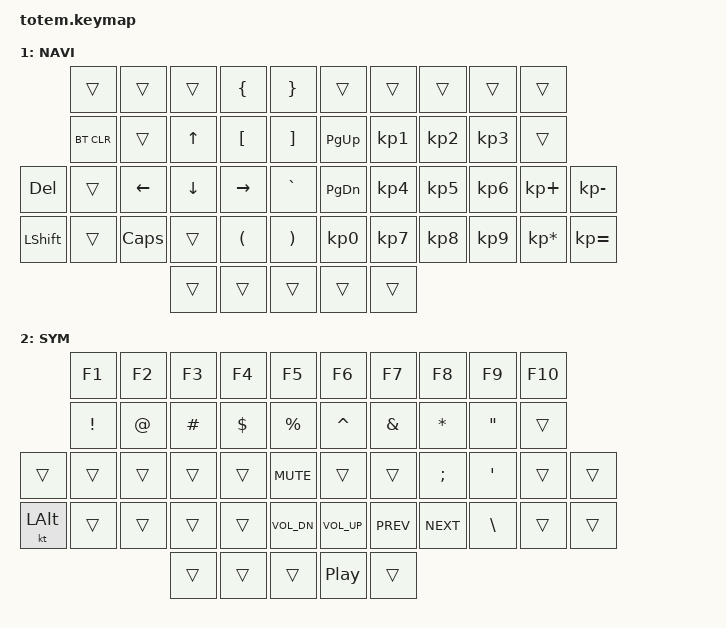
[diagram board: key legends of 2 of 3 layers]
//
//                                                        ▀▀▀▀▀     ▀▀▀▀▀          ▀▀█▀▀
//                                                        ▄▀▀▀▄  ▄  ▄▀▀▀▄  ▄  ▄▀▀▀▄  █  ▄▀▀▀▄
//                                                        █   █  █  █   █  █  █   █  █  █   █
//                                                         ▀▀▀   █   ▀▀▀   █   ▀▀▀   ▀   ▀▀▀
//                                                               █      ▄▄▄█▄▄▄    █   █
//                                                               ▀      █  █  █     █▄█
//                                                             ▀▀▀▀▀    █  █  █      ▀
//                                                                      ▀  ▀  ▀
//
// ▄▄▄▄▄▄▄▄▄▄▄▄▄▄▄▄▄▄▄▄▄▄▄▄▄▄▄▄▄▄▄▄▄▄▄▄▄▄▄▄▄▄▄▄▄▄▄▄▄▄▄▄▄▄▄▄▄▄▄▄▄▄▄▄▄▄▄▄▄▄▄▄▄▄▄▄▄▄▄▄▄▄▄▄▄▄▄▄▄▄▄▄▄▄▄▄▄▄▄▄▄▄▄▄▄▄▄▄▄▄▄▄▄▄▄▄▄▄▄▄▄▄▄▄▄▄▄▄▄▄▄▄▄▄▄▄▄▄▄▄▄▄▄▄▄▄▄▄▄

#include <behaviors.dtsi>
#include <dt-bindings/zmk/bt.h>
#include <dt-bindings/zmk/keys.h>

#define BASE 0
#define NAV  1
#define SYM  2
#define ADJ  3
#define TVP1 4
#define TVP2 5

&mt {
    quick-tap-ms = <100>;
    global-quick-tap;
    flavor = "tap-preferred";
    tapping-term-ms = <170>;
};

&lt {
    tapping-term-ms = <200>;
    flavor = "hold-preferred";
    quick-tap-ms = <125>;
};

/ {
    combos {
        compatible = "zmk,combos";

        combo_esc {
            timeout-ms = <50>;
            key-positions = <0 1>;
            bindings = <&kp ESC>;
        };

        combo_tvp {
            timeout-ms = <100>;
            key-positions = <11 12 13>;
            bindings = <&tog 0>;
        };
    };

    macros {
        gif: gif {
            label = "giphy";
            compatible = "zmk,behavior-macro";
            #binding-cells = <0>;
            bindings =
                <&macro_press>,
                <&kp LSHFT>,
                <&macro_tap>,
                <&kp N2>,
                <&macro_release>,
                <&kp LSHFT>,
                <&macro_tap>,
                <&kp G &kp I &kp F>;
        };
    };

    keymap {
        compatible = "zmk,keymap";

        // ▄▄▄▄▄▄▄▄▄▄▄▄▄▄▄▄▄▄▄▄▄▄▄▄▄▄▄▄▄▄▄▄▄▄▄▄▄▄▄▄▄▄▄▄▄▄▄▄▄▄▄▄▄▄▄▄▄▄▄▄▄▄▄▄▄▄▄▄▄▄▄▄▄▄▄▄▄▄▄▄▄▄▄▄▄▄▄▄▄▄▄▄▄▄▄▄▄▄▄▄▄▄▄▄▄▄▄▄▄▄▄▄▄▄▄▄▄▄▄▄▄▄▄▄▄▄▄▄▄▄▄▄▄▄▄▄▄▄▄▄▄▄▄▄▄▄▄▄▄

        base_layer {
            // ┏━━━━━━━━━━━━━━━━━━━━━━━━━━━━━━━━━━━━━━━┓

            label = "BASE";

            // ┗━━━━━━━━━━━━━━━━━━━━━━━━━━━━━━━━━━━━━━━┛
            // ┏━━━━━━━━━━━┳━━━━━━━━━━━┳━━━━━━━━━━━┳━━━━━━━━━━━┳━━━━━━━━━━━┓               ┏━━━━━━━━━━━┳━━━━━━━━━━━┳━━━━━━━━━━━┳━━━━━━━━━━━┳━━━━━━━━━━━┓
            // ┃     1     ┃     2     ┃     3     ┃     4     ┃     5     ┃               ┃     6     ┃     7     ┃     8     ┃     9     ┃     0     ┃
            // ┣━━━━━━━━━━━╋━━━━━━━━━━━╋━━━━━━━━━━━╋━━━━━━━━━━━╋━━━━━━━━━━━┫               ┣━━━━━━━━━━━╋━━━━━━━━━━━╋━━━━━━━━━━━╋━━━━━━━━━━━╋━━━━━━━━━━━┫
            //             ┃     Q     ┃     W     ┃     F     ┃     P     ┃     G     ┃   ┃     J     ┃     L     ┃     U     ┃     Y     ┃     ;     ┃
            //             ┣━━━━━━━━━━━╋━━━━━━━━━━━╋━━━━━━━━━━━╋━━━━━━━━━━━╋━━━━━━━━━━━┫   ┣━━━━━━━━━━━╋━━━━━━━━━━━╋━━━━━━━━━━━╋━━━━━━━━━━━╋━━━━━━━━━━━┫
            //             ┃     A     ┃     R     ┃     S     ┃     T     ┃     D     ┃   ┃     H     ┃     N     ┃     E     ┃     I     ┃     O     ┃
            // ┏━━━━━━━━━━━╋━━━━━━━━━━━╋━━━━━━━━━━━╋━━━━━━━━━━━╋━━━━━━━━━━━╋━━━━━━━━━━━┫   ┣━━━━━━━━━━━╋━━━━━━━━━━━╋━━━━━━━━━━━╋━━━━━━━━━━━╋━━━━━━━━━━━╋━━━━━━━━━━━┓
            // ┃     Q     ┃     Z     ┃     X     ┃     C     ┃     V     ┃     B     ┃   ┃     K     ┃     M     ┃     ,     ┃     .     ┃     /     ┃     \     ┃
            // ┗━━━━━━━━━━━┻━━━━━━━━━━━┻━━━━━━━━━━━╋━━━━━━━━━━━╋━━━━━━━━━━━╋━━━━━━━━━━━┫   ┣━━━━━━━━━━━╋━━━━━━━━━━━╋━━━━━━━━━━━╋━━━━━━━━━━━┻━━━━━━━━━━━┻━━━━━━━━━━━┛
            //                                     ┃    DEL    ┃    TAB    ┃    SPC    ┃   ┃   ENTER   ┃           ┃   BSPC    ┃
            //                                     ┗━━━━━━━━━━━┻━━━━━━━━━━━┻━━━━━━━━━━━┛   ┗━━━━━━━━━━━┻━━━━━━━━━━━┻━━━━━━━━━━━┛

            bindings = <
                &kp NUMBER_1  &kp NUMBER_2  &kp NUMBER_3      &kp NUMBER_4  &kp N5       &kp NUMBER_6  &kp N7           &kp N8       &kp N9      &kp N0
                &kp Q         &kp W         &kp E             &kp R         &kp T        &kp Y         &kp U            &kp I        &kp O       &kp P
&kp ESCAPE      &mt LGUI A    &mt LALT S    &mt LCTRL D       &mt LSHFT F   &kp G        &kp H         &mt RSHFT J      &mt RCTRL K  &mt RALT L  &mt RGUI DOUBLE_QUOTES  &kp MINUS
&kp LEFT_SHIFT  &kp Z         &kp X         &kp C             &kp V         &kp B        &kp N         &kp M            &kp COMMA    &kp DOT     &kp FSLH                &kp EQUAL
                                            &mt LCTRL ESCAPE  &lt 1 TAB     &kp SPACE    &kp SPACE     &lt 2 BACKSPACE  &kp ENTER
            >;
        };

        // ▄▄▄▄▄▄▄▄▄▄▄▄▄▄▄▄▄▄▄▄▄▄▄▄▄▄▄▄▄▄▄▄▄▄▄▄▄▄▄▄▄▄▄▄▄▄▄▄▄▄▄▄▄▄▄▄▄▄▄▄▄▄▄▄▄▄▄▄▄▄▄▄▄▄▄▄▄▄▄▄▄▄▄▄▄▄▄▄▄▄▄▄▄▄▄▄▄▄▄▄▄▄▄▄▄▄▄▄▄▄▄▄▄▄▄▄▄▄▄▄▄▄▄▄▄▄▄▄▄▄▄▄▄▄▄▄▄▄▄▄▄▄▄▄▄▄▄▄▄

        nav_layer {
            // ┏━━━━━━━━━━━━━━━━━━━━━━━━━━━━━━━━━━━━━━━┓

            label = "NAVI";

            // ┗━━━━━━━━━━━━━━━━━━━━━━━━━━━━━━━━━━━━━━━┛
            // ┏━━━━━━━━━━━┳━━━━━━━━━━━┳━━━━━━━━━━━┳━━━━━━━━━━━┳━━━━━━━━━━━┓   ┏━━━━━━━━━━━┳━━━━━━━━━━━┳━━━━━━━━━━━┳━━━━━━━━━━━┳━━━━━━━━━━━┓
            // ┃           ┃           ┃           ┃           ┃           ┃   ┃           ┃           ┃           ┃           ┃           ┃
            // ┣━━━━━━━━━━━╋━━━━━━━━━━━╋━━━━━━━━━━━╋━━━━━━━━━━━╋━━━━━━━━━━━┫   ┣━━━━━━━━━━━╋━━━━━━━━━━━╋━━━━━━━━━━━╋━━━━━━━━━━━╋━━━━━━━━━━━┫
            //             ┃           ┃           ┃     UP    ┃           ┃     {     ┃   ┃     }     ┃     7     ┃     8     ┃     9     ┃     +     ┃
            //             ┣━━━━━━━━━━━╋━━━━━━━━━━━╋━━━━━━━━━━━╋━━━━━━━━━━━╋━━━━━━━━━━━┫   ┣━━━━━━━━━━━╋━━━━━━━━━━━╋━━━━━━━━━━━╋━━━━━━━━━━━╋━━━━━━━━━━━┫
            //             ┃   SHIFT   ┃   LEFT    ┃    DOWN   ┃   RIGHT   ┃     [     ┃   ┃     ]     ┃     4     ┃     5     ┃     6     ┃     -     ┃
            // ┏━━━━━━━━━━━╋━━━━━━━━━━━╋━━━━━━━━━━━╋━━━━━━━━━━━╋━━━━━━━━━━━╋━━━━━━━━━━━┫   ┣━━━━━━━━━━━╋━━━━━━━━━━━╋━━━━━━━━━━━╋━━━━━━━━━━━╋━━━━━━━━━━━╋━━━━━━━━━━━┓
            // ┃           ┃           ┃   P UP    ┃  C LOCK   ┃  P DOWN   ┃     (     ┃   ┃     )     ┃     1     ┃     2     ┃     3     ┃     *     ┃           ┃
            // ┗━━━━━━━━━━━┻━━━━━━━━━━━┻━━━━━━━━━━━╋━━━━━━━━━━━╋━━━━━━━━━━━╋━━━━━━━━━━━┫   ┣━━━━━━━━━━━╋━━━━━━━━━━━╋━━━━━━━━━━━╋━━━━━━━━━━━┻━━━━━━━━━━━┻━━━━━━━━━━━┛
            //                                     ┃           ┃    TAB    ┃    SPC    ┃   ┃    DEL    ┃     0     ┃           ┃
            //                                     ┗━━━━━━━━━━━┻━━━━━━━━━━━┻━━━━━━━━━━━┛   ┗━━━━━━━━━━━┻━━━━━━━━━━━┻━━━━━━━━━━━┛

            bindings = <
                &trans      &trans    &trans        &kp LEFT_BRACE    &kp RIGHT_BRACE      &trans         &trans           &trans           &trans           &trans
                &bt BT_CLR  &trans    &kp UP_ARROW  &kp LEFT_BRACKET  &kp RIGHT_BRACKET    &kp PAGE_UP    &kp KP_NUMBER_1  &kp KP_N2        &kp KP_NUMBER_3  &trans
&kp DEL         &trans      &kp LEFT  &kp DOWN      &kp RIGHT         &kp GRAVE            &kp PAGE_DOWN  &kp KP_NUMBER_4  &kp KP_NUMBER_5  &kp KP_N6        &kp KP_PLUS      &kp KP_MINUS
&kp LEFT_SHIFT  &trans      &kp CAPS  &trans        &kp LPAR          &kp RPAR             &kp KP_N0      &kp KP_NUMBER_7  &kp KP_NUMBER_8  &kp KP_NUMBER_9  &kp KP_MULTIPLY  &kp KP_EQUAL
                                      &trans        &trans            &trans               &trans         &trans
            >;
        };

        // ▄▄▄▄▄▄▄▄▄▄▄▄▄▄▄▄▄▄▄▄▄▄▄▄▄▄▄▄▄▄▄▄▄▄▄▄▄▄▄▄▄▄▄▄▄▄▄▄▄▄▄▄▄▄▄▄▄▄▄▄▄▄▄▄▄▄▄▄▄▄▄▄▄▄▄▄▄▄▄▄▄▄▄▄▄▄▄▄▄▄▄▄▄▄▄▄▄▄▄▄▄▄▄▄▄▄▄▄▄▄▄▄▄▄▄▄▄▄▄▄▄▄▄▄▄▄▄▄▄▄▄▄▄▄▄▄▄▄▄▄▄▄▄▄▄▄▄▄▄

        sim_layer {
            // ┏━━━━━━━━━━━━━━━━━━━━━━━━━━━━━━━━━━━━━━━┓

            label = "SYM";

            // ┗━━━━━━━━━━━━━━━━━━━━━━━━━━━━━━━━━━━━━━━┛
            // ┏━━━━━━━━━━━┳━━━━━━━━━━━┳━━━━━━━━━━━┳━━━━━━━━━━━┳━━━━━━━━━━━┓   ┏━━━━━━━━━━━┳━━━━━━━━━━━┳━━━━━━━━━━━┳━━━━━━━━━━━┳━━━━━━━━━━━┓
            // ┃           ┃           ┃           ┃           ┃           ┃   ┃           ┃           ┃           ┃           ┃           ┃
            // ┣━━━━━━━━━━━╋━━━━━━━━━━━╋━━━━━━━━━━━╋━━━━━━━━━━━╋━━━━━━━━━━━┫   ┣━━━━━━━━━━━╋━━━━━━━━━━━╋━━━━━━━━━━━╋━━━━━━━━━━━╋━━━━━━━━━━━┫
            //             ┃     !     ┃     @     ┃     #     ┃     $     ┃     %     ┃   ┃     ˆ     ┃     &     ┃     Ü     ┃     '     ┃     "     ┃
            //             ┣━━━━━━━━━━━╋━━━━━━━━━━━╋━━━━━━━━━━━╋━━━━━━━━━━━╋━━━━━━━━━━━┫   ┣━━━━━━━━━━━╋━━━━━━━━━━━╋━━━━━━━━━━━╋━━━━━━━━━━━╋━━━━━━━━━━━┫
            //             ┃     Ä     ┃           ┃    SZ     ┃           ┃           ┃   ┃   MUTE    ┃   YEN     ┃   EURO    ┃  POUND    ┃     Ö     ┃
            // ┏━━━━━━━━━━━╋━━━━━━━━━━━╋━━━━━━━━━━━╋━━━━━━━━━━━╋━━━━━━━━━━━╋━━━━━━━━━━━┫   ┣━━━━━━━━━━━╋━━━━━━━━━━━╋━━━━━━━━━━━╋━━━━━━━━━━━╋━━━━━━━━━━━╋━━━━━━━━━━━┓
            // ┃           ┃  EMAIL1   ┃  EMAIL2   ┃           ┃           ┃           ┃   ┃   VOL-    ┃   VOL+    ┃   LAST    ┃   NEXT    ┃     \     ┃           ┃
            // ┗━━━━━━━━━━━┻━━━━━━━━━━━┻━━━━━━━━━━━╋━━━━━━━━━━━╋━━━━━━━━━━━╋━━━━━━━━━━━┫   ┣━━━━━━━━━━━╋━━━━━━━━━━━╋━━━━━━━━━━━╋━━━━━━━━━━━┻━━━━━━━━━━━┻━━━━━━━━━━━┛
            //                                     ┃           ┃    GIF    ┃    ADJ    ┃   ┃           ┃           ┃           ┃
            //                                     ┗━━━━━━━━━━━┻━━━━━━━━━━━┻━━━━━━━━━━━┛   ┗━━━━━━━━━━━┻━━━━━━━━━━━┻━━━━━━━━━━━┛

            bindings = <
              &kp F1           &kp F2       &kp F3    &kp F4      &kp F5          &kp F6        &kp F7         &kp F8         &kp F9    &kp F10
              &kp EXCLAMATION  &kp AT_SIGN  &kp HASH  &kp DOLLAR  &kp PERCENT     &kp CARET     &kp AMPERSAND  &kp ASTERISK   &kp DQT   &trans
&trans        &trans           &trans       &trans    &trans      &kp C_MUTE      &trans        &trans         &kp SEMICOLON  &kp SQT   &trans   &trans
&kt LEFT_ALT  &trans           &trans       &trans    &trans      &kp C_VOL_DN    &kp C_VOL_UP  &kp C_PREV     &kp C_NEXT     &kp BSLH  &trans   &trans
                                            &trans    &trans      &trans          &kp C_PP      &trans
            >;
        };

        // ▄▄▄▄▄▄▄▄▄▄▄▄▄▄▄▄▄▄▄▄▄▄▄▄▄▄▄▄▄▄▄▄▄▄▄▄▄▄▄▄▄▄▄▄▄▄▄▄▄▄▄▄▄▄▄▄▄▄▄▄▄▄▄▄▄▄▄▄▄▄▄▄▄▄▄▄▄▄▄▄▄▄▄▄▄▄▄▄▄▄▄▄▄▄▄▄▄▄▄▄▄▄▄▄▄▄▄▄▄▄▄▄▄▄▄▄▄▄▄▄▄▄▄▄▄▄▄▄▄▄▄▄▄▄▄▄▄▄▄▄▄▄▄▄▄▄▄▄▄
        // ▄▄▄▄▄▄▄▄▄▄▄▄▄▄▄▄▄▄▄▄▄▄▄▄▄▄▄▄▄▄▄▄▄▄▄▄▄▄▄▄▄▄▄▄▄▄▄▄▄▄▄▄▄▄▄▄▄▄▄▄▄▄▄▄▄▄▄▄▄▄▄▄▄▄▄▄▄▄▄▄▄▄▄▄▄▄▄▄▄▄▄▄▄▄▄▄▄▄▄▄▄▄▄▄▄▄▄▄▄▄▄▄▄▄▄▄▄▄▄▄▄▄▄▄▄▄▄▄▄▄▄▄▄▄▄▄▄▄▄▄▄▄▄▄▄▄▄▄▄
        // ▄▄▄▄▄▄▄▄▄▄▄▄▄▄▄▄▄▄▄▄▄▄▄▄▄▄▄▄▄▄▄▄▄▄▄▄▄▄▄▄▄▄▄▄▄▄▄▄▄▄▄▄▄▄▄▄▄▄▄▄▄▄▄▄▄▄▄▄▄▄▄▄▄▄▄▄▄▄▄▄▄▄▄▄▄▄▄▄▄▄▄▄▄▄▄▄▄▄▄▄▄▄▄▄▄▄▄▄▄▄▄▄▄▄▄▄▄▄▄▄▄▄▄▄▄▄▄▄▄▄▄▄▄▄▄▄▄▄▄▄▄▄▄▄▄▄▄▄▄
    };
};
